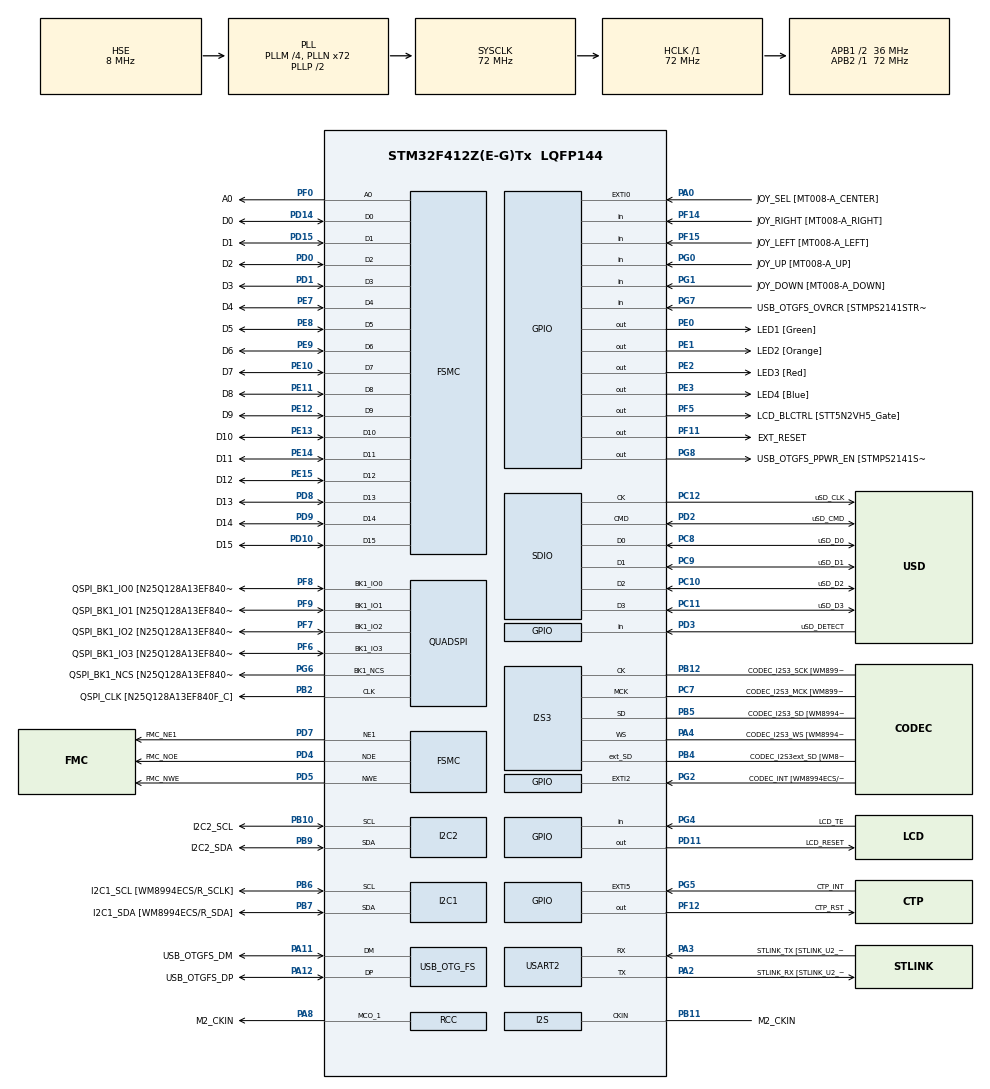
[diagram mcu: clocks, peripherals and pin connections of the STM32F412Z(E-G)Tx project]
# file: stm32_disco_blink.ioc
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PD7.Mode=NorPsramChipSelect1_1
PG8.GPIO_ModeDefaultOutputPP=GPIO_MODE_OUTPUT_OD
SH.FSMC_D1_DA1.0=FSMC_D1,16b-d1
PB10.Mode=I2C
PG8.Signal=GPIO_Output
PG4.Signal=GPIO_Input
PC12.Signal=SDIO_CK
PG6.GPIO_Label=QSPI_BK1_NCS [N25Q128A13EF840F_S]
PA14.GPIO_Label=SWCLK
SH.FSMC_NWE.0=FSMC_NWE,Lcd1
PG0.Signal=GPIO_Input
SDIO.WideMode=SDIO_BUS_WIDE_4B
PB6.GPIO_Label=I2C1_SCL [WM8994ECS/R_SCLK]
PG6.Mode=Single Bank 1
PF6.GPIO_Label=QSPI_BK1_IO3 [N25Q128A13EF840F_DQ3]
RCC.SYSCLKSource=RCC_SYSCLKSOURCE_PLLCLK
PE1.GPIO_ModeDefaultOutputPP=GPIO_MODE_OUTPUT_OD
PA4.Mode=Full_Duplex_Master
PF7.Signal=QUADSPI_BK1_IO2
PD4.Signal=FSMC_NOE
RCC.APB2TimFreq_Value=72000000
PB6.Signal=I2C1_SCL
PC7.Signal=I2S3_MCK
PB6.Mode=I2C
PD0.Signal=FSMC_D2_DA2
PD8.Signal=FSMC_D13_DA13
PE1.Signal=GPIO_Output
USB_OTG_FS.phy_itface=HCD_PHY_EMBEDDED
PB2.Signal=QUADSPI_CLK
PD1.GPIO_Label=D3
PB12.GPIO_Label=CODEC_I2S3_SCK [WM8994ECS/R_BCLK1]
PF12.GPIO_Label=CTP_RST
I2S3.ErrorAudioFreq=1.72 %
SH.FSMC_D10_DA10.0=FSMC_D10,16b-d1
PE9.Signal=FSMC_D6_DA6
SH.FSMC_A0.0=FSMC_A0,A0_1
PB1.GPIO_Label=DFSDM_DATIN0 [MP34DT01TR_DOUT]
PG4.GPIO_Label=LCD_TE
PE4.GPIO_Label=DFSDM_DATIN3 [MP23DB01MM_DOUT]
PC9.Mode=SD_4_bits_Wide_bus
PE2.Signal=GPIO_Output
PF8.Mode=Single Bank 1
PA8.Signal=RCC_MCO_1
PE10.Signal=FSMC_D7_DA7
SH.FSMC_D5_DA5.0=FSMC_D5,16b-d1
PA0.Signal=GPXTI0
Mcu.Package=LQFP144
PB9.Signal=I2C2_SDA
PB1.Signal=S_DATAIN0DFSDM1
PA10.Signal=USB_OTG_FS_ID
PE12.GPIO_Label=D9
PC11.Mode=SD_4_bits_Wide_bus
SH.FSMC_D3_DA3.0=FSMC_D3,16b-d1
PF14.Signal=GPIO_Input
RCC.APB1TimFreq_Value=72000000
PE10.GPIO_Label=D7
PA4.GPIO_Label=CODEC_I2S3_WS [WM8994ECS/R_LRCLK1]
PD15.Signal=FSMC_D1_DA1
I2S3.FullDuplexMode=I2S_FULLDUPLEXMODE_ENABLE
PD9.GPIO_Label=D14
PG5.Signal=GPXTI5
PA9.GPIO_Label=USB_OTGFS_VBUS
PD3.Signal=GPIO_Input
PH1\ -\ OSC_OUT.Mode=HSE-External-Clock-Source
PC2.Signal=S_CKOUTDFSDM1
PB11.GPIO_Label=M2_CKIN
PD7.Signal=FSMC_NE1
PD1.Signal=FSMC_D3_DA3
PA11.GPIO_Label=USB_OTGFS_DM
SH.FSMC_D9_DA9.0=FSMC_D9,16b-d1
PF14.GPIO_Label=JOY_RIGHT [MT008-A_RIGHT]
RCC.APB1CLKDivider=RCC_HCLK_DIV2
PC14-OSC32_IN.Signal=RCC_OSC32_IN
SH.FSMC_D8_DA8.0=FSMC_D8,16b-d1
PF8.GPIO_Label=QSPI_BK1_IO0 [N25Q128A13EF840F_DQ0]
USB_HOST0.BSP.STBoard=false
PD10.Signal=FSMC_D15_DA15
PA3.Mode=Asynchronous
PA8.GPIO_Label=M2_CKIN
PB11.Mode=Audio_ClockIn
PE8.GPIO_Label=D5
PA9.Signal=USB_OTG_FS_VBUS
I2S3.VirtualMode=I2S_MODE_MASTER
PE9.GPIO_Label=D6
PB10.Signal=I2C2_SCL
I2S3.AudioFreq=I2S_AUDIOFREQ_32K
PC12.Mode=SD_4_bits_Wide_bus
PH1\ -\ OSC_OUT.Signal=RCC_OSC_OUT
SH.FSMC_D7_DA7.0=FSMC_D7,16b-d1
PE1.GPIO_Label=LED2 [Orange]
USB_HOST.VirtualModeFS=Cdc
PE14.Signal=FSMC_D11_DA11
PE15.Signal=FSMC_D12_DA12
PB4.GPIO_Label=CODEC_I2S3ext_SD [WM8994ECS/R_ACDAT1]
PE8.Signal=FSMC_D5_DA5
PG7.GPIO_Label=USB_OTGFS_OVRCR [STMPS2141STR_FAULT]
SH.S_DATAIN0DFSDM1.0=DFSDM1_DATIN0
PA13.Mode=Serial_Wire
PC7.GPIO_Label=CODEC_I2S3_MCK [WM8994ECS/R_MCLK1]
PC8.Mode=SD_4_bits_Wide_bus
PA4.Signal=I2S3_WS
PB5.Signal=I2S3_SD
PE13.GPIO_Label=D10
PE3.GPIO_ModeDefaultOutputPP=GPIO_MODE_OUTPUT_OD
PD11.Signal=GPIO_Output
PC12.GPIO_Label=uSD_CLK
PA11.Signal=USB_OTG_FS_DM
SH.FSMC_D15_DA15.0=FSMC_D15,16b-d1
ProjectManager.HeapSize=0x200
PF6.Mode=Single Bank 1
PF9.Signal=QUADSPI_BK1_IO1
USB_HOST.USBH_HandleTypeDef=hUsbHostFS
NVIC.PriorityGroup=NVIC_PRIORITYGROUP_4
PF0.GPIO_Label=A0
PE3.Signal=GPIO_Output
PA8.Mode=Clock-out-1
I2S3.Instance=SPI$Index
PD2.Signal=SDIO_CMD
USB_HOST0.BSP.mode=Output
PD2.GPIO_Label=uSD_CMD
Mcu.Family=STM32F4
RCC.CortexFreq_Value=72000000
PG6.Signal=QUADSPI_BK1_NCS
PG2.Signal=GPXTI2
PE11.GPIO_Label=D8
PC10.Signal=SDIO_D2
PA0.GPIO_Label=JOY_SEL [MT008-A_CENTER]
SH.FSMC_D0_DA0.0=FSMC_D0,16b-d1
PD0.GPIO_Label=D2
PA11.Mode=Host_Only
PG5.GPIO_Label=CTP_INT
PB11.Signal=I2S_CKIN
ProjectManager.StackSize=0x400
PA12.Signal=USB_OTG_FS_DP
PH0\ -\ OSC_IN.Signal=RCC_OSC_IN
PD11.GPIO_Label=LCD_RESET
RCC.HCLKFreq_Value=72000000
PF11.GPIO_Label=EXT_RESET
PF12.Signal=GPIO_Output
USB_HOST0.BSP.ip=GPIO
RCC.AHBFreq_Value=72000000
RCC.HSE_VALUE=8000000
PE2.GPIO_ModeDefaultOutputPP=GPIO_MODE_OUTPUT_OD
PF9.Mode=Single Bank 1
PB4.Mode=Full_Duplex_Master
PE13.Signal=FSMC_D10_DA10
SH.FSMC_D14_DA14.0=FSMC_D14,16b-d1
PF7.GPIO_Label=QSPI_BK1_IO2 [N25Q128A13EF840F_DQ2]
PC14-OSC32_IN.Mode=LSE-External-Oscillator
PA14.Mode=Serial_Wire
PF11.Signal=GPIO_Output
SH.FSMC_D6_DA6.0=FSMC_D6,16b-d1
PC11.GPIO_Label=uSD_D3
PB5.Mode=Full_Duplex_Master
PA10.GPIO_Label=USB_OTGFS_ID
PB7.Signal=I2C1_SDA
USB_HOST0.BSP.i2creg=0
PE4.Signal=S_DATAIN3DFSDM1
PD7.GPIO_Label=FMC_NE1
SH.FSMC_D4_DA4.0=FSMC_D4,16b-d1
PB7.GPIO_Label=I2C1_SDA [WM8994ECS/R_SDA]
USB_HOST0.BSP.i2caddr=0
PB12.Mode=Full_Duplex_Master
USART2.VirtualMode=VM_ASYNC
PD5.GPIO_Label=FMC_NWE
NVIC.OTG_FS_IRQn=true\:0\:0\:false\:false\:true\:true\:true
PA2.GPIO_Label=STLINK_RX [STLINK_U2_RX]
SH.FSMC_D13_DA13.0=FSMC_D13,16b-d1
PF5.GPIO_Label=LCD_BLCTRL [STT5N2VH5_Gate]
USB_OTG_FS.VirtualMode=Host_Only
PF8.Signal=QUADSPI_BK1_IO0
PG0.GPIO_Label=JOY_UP [MT008-A_UP]
PE0.GPIO_Label=LED1 [Green]
PF5.Signal=GPIO_Output
USB_HOST0.BSP.name=Drive_VBUS_FS
PB5.GPIO_Label=CODEC_I2S3_SD [WM8994ECS/R_DACDAT1]
PG8.PinState=GPIO_PIN_SET
SH.FSMC_D2_DA2.0=FSMC_D2,16b-d1
PF0.Signal=FSMC_A0
PD3.GPIO_Label=uSD_DETECT
PE7.Signal=FSMC_D4_DA4
PE2.GPIO_Label=LED3 [Red]
PC2.GPIO_Label=DFSDM_CKOUT [MP34DT01TR_CLK]
PB4.Signal=I2S3_ext_SD
PG2.GPIO_Label=CODEC_INT [WM8994ECS/R_ADCLRCLK1/GPIO1]
PA3.Signal=USART2_RX
PB3.GPIO_Label=SWO
PC15-OSC32_OUT.Mode=LSE-External-Oscillator
PE0.GPIO_ModeDefaultOutputPP=GPIO_MODE_OUTPUT_OD
SH.FSMC_D12_DA12.0=FSMC_D12,16b-d1
PD15.GPIO_Label=D1
PG7.Signal=GPIO_Input
PB9.GPIO_Label=I2C2_SDA
PC10.GPIO_Label=uSD_D2
PC9.GPIO_Label=uSD_D1
PG1.Signal=GPIO_Input
PC11.Signal=SDIO_D3
PC8.Signal=SDIO_D0
USB_HOST0.BSP.solution=PG8
PC10.Mode=SD_4_bits_Wide_bus
USB_HOST.BSP.number=1
PE14.GPIO_Label=D11
PD9.Signal=FSMC_D14_DA14
PD5.Signal=FSMC_NWE
PA12.GPIO_Label=USB_OTGFS_DP
PD8.GPIO_Label=D13
PG8.GPIO_Label=USB_OTGFS_PPWR_EN [STMPS2141STR_EN]
PC8.GPIO_Label=uSD_D0
PA13.Signal=SYS_JTMS-SWDIO
PF7.Mode=Single Bank 1
PH0\ -\ OSC_IN.Mode=HSE-External-Clock-Source
PE15.GPIO_Label=D12
PF6.Signal=QUADSPI_BK1_IO3
ProjectManager.TargetToolchain=SW4STM32
PB10.GPIO_Label=I2C2_SCL
PB9.Mode=I2C
RCC.USBFreq_Value=48000000
PF9.GPIO_Label=QSPI_BK1_IO1 [N25Q128A13EF840F_DQ1]
PD10.GPIO_Label=D15
PE11.Signal=FSMC_D8_DA8
PC15-OSC32_OUT.Signal=RCC_OSC32_OUT
PD2.Mode=SD_4_bits_Wide_bus
board=STM32F412G-DISCO
RCC.VCOOutputFreq_Value=144000000
PG1.GPIO_Label=JOY_DOWN [MT008-A_DOWN]
RCC.APB2Freq_Value=72000000
USB_HOST0.BSP.api=Unknown
PD4.GPIO_Label=FMC_NOE
SH.S_CKOUTDFSDM1.0=DFSDM1_CKOUT
SH.S_DATAIN3DFSDM1.0=DFSDM1_DATIN3
PF15.GPIO_Label=JOY_LEFT [MT008-A_LEFT]
PF15.Signal=GPIO_Input
PD14.GPIO_Label=D0
Mcu.Name=STM32F412Z(E-G)Tx
PE0.Signal=GPIO_Output
PE7.GPIO_Label=D4
PE12.Signal=FSMC_D9_DA9
PA2.Signal=USART2_TX
PA13.GPIO_Label=SWDIO
PD14.Signal=FSMC_D0_DA0
RCC.48MHZClocksFreq_Value=48000000
PB3.Signal=SYS_JTDO-SWO
RCC.SYSCLKFreq_VALUE=72000000
PA12.Mode=Host_Only
VP_USB_HOST_VS_USB_HOST_CDC_FS.Mode=CDC_FS
PB2.Mode=Single Bank 1
PB7.Mode=I2C
PA14.Signal=SYS_JTCK-SWCLK
PB2.GPIO_Label=QSPI_CLK [N25Q128A13EF840F_C]
SH.FSMC_D11_DA11.0=FSMC_D11,16b-d1
SH.FSMC_NOE.0=FSMC_NOE,Lcd1
RCC.HSI_VALUE=16000000
RCC.PLLQ=3
I2S3.RealAudioFreq=32.552 KHz
RCC.PLLM=4
RCC.PLLN=72
PA2.Mode=Asynchronous
PE3.GPIO_Label=LED4 [Blue]
PH0\ -\ OSC_IN.GPIO_Label=STLK_MCO
PC9.Signal=SDIO_D1
PC7.Mode=Master_Clock_Activated
RCC.APB1Freq_Value=36000000
RCC.PLLI2SN=50
PB12.Signal=I2S3_CK
PA3.GPIO_Label=STLINK_TX [STLINK_U2_TX]
RCC.PLLI2SM=4
USB_HOST0.BSP.instance=PG8

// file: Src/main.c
/* USER CODE BEGIN Header */
/**
  ******************************************************************************
  * @file           : main.c
  * @brief          : Main program body
  ******************************************************************************
  * @attention
  *
  * <h2><center>&copy; Copyright (c) 2020 STMicroelectronics.
  * All rights reserved.</center></h2>
  *
  * This software component is licensed by ST under Ultimate Liberty license
  * SLA0044, the "License"; You may not use this file except in compliance with
  * the License. You may obtain a copy of the License at:
  *                             www.st.com/SLA0044
  *
  ******************************************************************************
  */
/* USER CODE END Header */

#include "main.h"
#include "usb_host.h"

/* USER CODE BEGIN Includes */
#include "stm32412g_discovery.h"
/* USER CODE END Includes */

I2C_HandleTypeDef hi2c1;
I2C_HandleTypeDef hi2c2;

I2S_HandleTypeDef hi2s3;

QSPI_HandleTypeDef hqspi;

SD_HandleTypeDef hsd;

UART_HandleTypeDef huart2;

SRAM_HandleTypeDef hsram1;

void SystemClock_Config(void);
static void MX_GPIO_Init(void);
static void MX_FSMC_Init(void);
static void MX_I2C1_Init(void);
static void MX_I2C2_Init(void);
static void MX_I2S3_Init(void);
static void MX_QUADSPI_Init(void);
static void MX_SDIO_SD_Init(void);
static void MX_USART2_UART_Init(void);
void MX_USB_HOST_Process(void);

int main(void)
{

  /* MCU Configuration--------------------------------------------------------*/

  /* Reset of all peripherals, Initializes the Flash interface and the Systick. */
  HAL_Init();

  /* Configure the system clock */
  SystemClock_Config();

  /* Initialize all configured peripherals */
  MX_GPIO_Init();
  MX_FSMC_Init();
  MX_I2C1_Init();
  MX_I2C2_Init();
  MX_I2S3_Init();
  MX_QUADSPI_Init();
  MX_SDIO_SD_Init();
  MX_USART2_UART_Init();
  MX_USB_HOST_Init();
  /* USER CODE BEGIN 2 */
  BSP_LED_Init(LED_BLUE);
  BSP_LED_Init(LED_RED);
  BSP_LED_Init(LED_ORANGE);
  BSP_LED_Init(LED_GREEN);

  BSP_LED_On(LED_GREEN);
  /* USER CODE END 2 */

  /* Infinite loop */
  while (1)
  {
    MX_USB_HOST_Process();

    /* USER CODE BEGIN 3 */
    BSP_LED_Toggle(LED_BLUE);

    HAL_UART_Transmit(&huart2, (uint8_t*)"BTS SNIR Sembat\r\n", 17, 1000);

    HAL_Delay(400);
  }
  /* USER CODE END 3 */
}

void SystemClock_Config(void)
{
  RCC_OscInitTypeDef RCC_OscInitStruct = {0};
  RCC_ClkInitTypeDef RCC_ClkInitStruct = {0};
  RCC_PeriphCLKInitTypeDef PeriphClkInitStruct = {0};

  /** Configure the main internal regulator output voltage
  */
  __HAL_RCC_PWR_CLK_ENABLE();
  __HAL_PWR_VOLTAGESCALING_CONFIG(PWR_REGULATOR_VOLTAGE_SCALE1);
  /** Initializes the CPU, AHB and APB busses clocks
  */
  RCC_OscInitStruct.OscillatorType = RCC_OSCILLATORTYPE_HSI|RCC_OSCILLATORTYPE_HSE;
  RCC_OscInitStruct.HSEState = RCC_HSE_BYPASS;
  RCC_OscInitStruct.HSIState = RCC_HSI_ON;
  RCC_OscInitStruct.HSICalibrationValue = RCC_HSICALIBRATION_DEFAULT;
  RCC_OscInitStruct.PLL.PLLState = RCC_PLL_ON;
  RCC_OscInitStruct.PLL.PLLSource = RCC_PLLSOURCE_HSE;
  RCC_OscInitStruct.PLL.PLLM = 4;
  RCC_OscInitStruct.PLL.PLLN = 72;
  RCC_OscInitStruct.PLL.PLLP = RCC_PLLP_DIV2;
  RCC_OscInitStruct.PLL.PLLQ = 3;
  RCC_OscInitStruct.PLL.PLLR = 2;
  if (HAL_RCC_OscConfig(&RCC_OscInitStruct) != HAL_OK)
  {
    Error_Handler();
  }
  /** Initializes the CPU, AHB and APB busses clocks
  */
  RCC_ClkInitStruct.ClockType = RCC_CLOCKTYPE_HCLK|RCC_CLOCKTYPE_SYSCLK
                              |RCC_CLOCKTYPE_PCLK1|RCC_CLOCKTYPE_PCLK2;
  RCC_ClkInitStruct.SYSCLKSource = RCC_SYSCLKSOURCE_PLLCLK;
  RCC_ClkInitStruct.AHBCLKDivider = RCC_SYSCLK_DIV1;
  RCC_ClkInitStruct.APB1CLKDivider = RCC_HCLK_DIV2;
  RCC_ClkInitStruct.APB2CLKDivider = RCC_HCLK_DIV1;

  if (HAL_RCC_ClockConfig(&RCC_ClkInitStruct, FLASH_LATENCY_2) != HAL_OK)
  {
    Error_Handler();
  }
  PeriphClkInitStruct.PeriphClockSelection = RCC_PERIPHCLK_I2S_APB1|RCC_PERIPHCLK_SDIO
                              |RCC_PERIPHCLK_CLK48;
  PeriphClkInitStruct.PLLI2S.PLLI2SN = 50;
  PeriphClkInitStruct.PLLI2S.PLLI2SM = 4;
  PeriphClkInitStruct.PLLI2S.PLLI2SR = 2;
  PeriphClkInitStruct.PLLI2S.PLLI2SQ = 2;
  PeriphClkInitStruct.Clk48ClockSelection = RCC_CLK48CLKSOURCE_PLLQ;
  PeriphClkInitStruct.SdioClockSelection = RCC_SDIOCLKSOURCE_CLK48;
  PeriphClkInitStruct.PLLI2SSelection = RCC_PLLI2SCLKSOURCE_PLLSRC;
  PeriphClkInitStruct.I2sApb1ClockSelection = RCC_I2SAPB1CLKSOURCE_PLLI2S;
  if (HAL_RCCEx_PeriphCLKConfig(&PeriphClkInitStruct) != HAL_OK)
  {
    Error_Handler();
  }
  HAL_RCC_MCOConfig(RCC_MCO1, RCC_MCO1SOURCE_HSI, RCC_MCODIV_1);
}

static void MX_I2C1_Init(void)
{

  hi2c1.Instance = I2C1;
  hi2c1.Init.ClockSpeed = 100000;
  hi2c1.Init.DutyCycle = I2C_DUTYCYCLE_2;
  hi2c1.Init.OwnAddress1 = 0;
  hi2c1.Init.AddressingMode = I2C_ADDRESSINGMODE_7BIT;
  hi2c1.Init.DualAddressMode = I2C_DUALADDRESS_DISABLE;
  hi2c1.Init.OwnAddress2 = 0;
  hi2c1.Init.GeneralCallMode = I2C_GENERALCALL_DISABLE;
  hi2c1.Init.NoStretchMode = I2C_NOSTRETCH_DISABLE;
  if (HAL_I2C_Init(&hi2c1) != HAL_OK)
  {
    Error_Handler();
  }

}

static void MX_I2C2_Init(void)
{

  hi2c2.Instance = I2C2;
  hi2c2.Init.ClockSpeed = 100000;
  hi2c2.Init.DutyCycle = I2C_DUTYCYCLE_2;
  hi2c2.Init.OwnAddress1 = 0;
  hi2c2.Init.AddressingMode = I2C_ADDRESSINGMODE_7BIT;
  hi2c2.Init.DualAddressMode = I2C_DUALADDRESS_DISABLE;
  hi2c2.Init.OwnAddress2 = 0;
  hi2c2.Init.GeneralCallMode = I2C_GENERALCALL_DISABLE;
  hi2c2.Init.NoStretchMode = I2C_NOSTRETCH_DISABLE;
  if (HAL_I2C_Init(&hi2c2) != HAL_OK)
  {
    Error_Handler();
  }

}

static void MX_I2S3_Init(void)
{

  hi2s3.Instance = SPI3;
  hi2s3.Init.Mode = I2S_MODE_MASTER_TX;
  hi2s3.Init.Standard = I2S_STANDARD_PHILIPS;
  hi2s3.Init.DataFormat = I2S_DATAFORMAT_16B;
  hi2s3.Init.MCLKOutput = I2S_MCLKOUTPUT_ENABLE;
  hi2s3.Init.AudioFreq = I2S_AUDIOFREQ_32K;
  hi2s3.Init.CPOL = I2S_CPOL_LOW;
  hi2s3.Init.ClockSource = I2S_CLOCK_PLL;
  hi2s3.Init.FullDuplexMode = I2S_FULLDUPLEXMODE_ENABLE;
  if (HAL_I2S_Init(&hi2s3) != HAL_OK)
  {
    Error_Handler();
  }

}

static void MX_QUADSPI_Init(void)
{

  /* QUADSPI parameter configuration*/
  hqspi.Instance = QUADSPI;
  hqspi.Init.ClockPrescaler = 255;
  hqspi.Init.FifoThreshold = 1;
  hqspi.Init.SampleShifting = QSPI_SAMPLE_SHIFTING_NONE;
  hqspi.Init.FlashSize = 1;
  hqspi.Init.ChipSelectHighTime = QSPI_CS_HIGH_TIME_1_CYCLE;
  hqspi.Init.ClockMode = QSPI_CLOCK_MODE_0;
  hqspi.Init.FlashID = QSPI_FLASH_ID_1;
  hqspi.Init.DualFlash = QSPI_DUALFLASH_DISABLE;
  if (HAL_QSPI_Init(&hqspi) != HAL_OK)
  {
    Error_Handler();
  }

}

static void MX_SDIO_SD_Init(void)
{

  hsd.Instance = SDIO;
  hsd.Init.ClockEdge = SDIO_CLOCK_EDGE_RISING;
  hsd.Init.ClockBypass = SDIO_CLOCK_BYPASS_DISABLE;
  hsd.Init.ClockPowerSave = SDIO_CLOCK_POWER_SAVE_DISABLE;
  hsd.Init.BusWide = SDIO_BUS_WIDE_1B;
  hsd.Init.HardwareFlowControl = SDIO_HARDWARE_FLOW_CONTROL_DISABLE;
  hsd.Init.ClockDiv = 0;
  if (HAL_SD_Init(&hsd) != HAL_OK)
  {
    Error_Handler();
  }
  if (HAL_SD_ConfigWideBusOperation(&hsd, SDIO_BUS_WIDE_4B) != HAL_OK)
  {
    Error_Handler();
  }

}

static void MX_USART2_UART_Init(void)
{

  huart2.Instance = USART2;
  huart2.Init.BaudRate = 115200;
  huart2.Init.WordLength = UART_WORDLENGTH_8B;
  huart2.Init.StopBits = UART_STOPBITS_1;
  huart2.Init.Parity = UART_PARITY_NONE;
  huart2.Init.Mode = UART_MODE_TX_RX;
  huart2.Init.HwFlowCtl = UART_HWCONTROL_NONE;
  huart2.Init.OverSampling = UART_OVERSAMPLING_16;
  if (HAL_UART_Init(&huart2) != HAL_OK)
  {
    Error_Handler();
  }

}

static void MX_GPIO_Init(void)
{
  GPIO_InitTypeDef GPIO_InitStruct = {0};

  /* GPIO Ports Clock Enable */
  __HAL_RCC_GPIOE_CLK_ENABLE();
  __HAL_RCC_GPIOC_CLK_ENABLE();
  __HAL_RCC_GPIOF_CLK_ENABLE();
  __HAL_RCC_GPIOH_CLK_ENABLE();
  __HAL_RCC_GPIOA_CLK_ENABLE();
  __HAL_RCC_GPIOB_CLK_ENABLE();
  __HAL_RCC_GPIOG_CLK_ENABLE();
  __HAL_RCC_GPIOD_CLK_ENABLE();

  /*Configure GPIO pin Output Level */
  HAL_GPIO_WritePin(GPIOE, LED3_Pin|LED4_Pin|LED1_Pin|LED2_Pin, GPIO_PIN_RESET);

  /*Configure GPIO pin Output Level */
  HAL_GPIO_WritePin(GPIOF, LCD_BLCTRL_Pin|EXT_RESET_Pin|CTP_RST_Pin, GPIO_PIN_RESET);

  /*Configure GPIO pin Output Level */
  HAL_GPIO_WritePin(LCD_RESET_GPIO_Port, LCD_RESET_Pin, GPIO_PIN_RESET);

  /*Configure GPIO pin Output Level */
  HAL_GPIO_WritePin(USB_OTGFS_PPWR_EN_GPIO_Port, USB_OTGFS_PPWR_EN_Pin, GPIO_PIN_SET);

  /*Configure GPIO pins : LED3_Pin LED4_Pin LED1_Pin LED2_Pin */
  GPIO_InitStruct.Pin = LED3_Pin|LED4_Pin|LED1_Pin|LED2_Pin;
  GPIO_InitStruct.Mode = GPIO_MODE_OUTPUT_OD;
  GPIO_InitStruct.Pull = GPIO_NOPULL;
  GPIO_InitStruct.Speed = GPIO_SPEED_FREQ_LOW;
  HAL_GPIO_Init(GPIOE, &GPIO_InitStruct);

  /*Configure GPIO pin : DFSDM_DATIN3_Pin */
  GPIO_InitStruct.Pin = DFSDM_DATIN3_Pin;
  GPIO_InitStruct.Mode = GPIO_MODE_AF_PP;
  GPIO_InitStruct.Pull = GPIO_NOPULL;
  GPIO_InitStruct.Speed = GPIO_SPEED_FREQ_LOW;
  GPIO_InitStruct.Alternate = GPIO_AF8_DFSDM1;
  HAL_GPIO_Init(DFSDM_DATIN3_GPIO_Port, &GPIO_InitStruct);

  /*Configure GPIO pins : LCD_BLCTRL_Pin EXT_RESET_Pin CTP_RST_Pin */
  GPIO_InitStruct.Pin = LCD_BLCTRL_Pin|EXT_RESET_Pin|CTP_RST_Pin;
  GPIO_InitStruct.Mode = GPIO_MODE_OUTPUT_PP;
  GPIO_InitStruct.Pull = GPIO_NOPULL;
  GPIO_InitStruct.Speed = GPIO_SPEED_FREQ_LOW;
  HAL_GPIO_Init(GPIOF, &GPIO_InitStruct);

  /*Configure GPIO pin : DFSDM_CKOUT_Pin */
  GPIO_InitStruct.Pin = DFSDM_CKOUT_Pin;
  GPIO_InitStruct.Mode = GPIO_MODE_AF_PP;
  GPIO_InitStruct.Pull = GPIO_NOPULL;
  GPIO_InitStruct.Speed = GPIO_SPEED_FREQ_LOW;
  GPIO_InitStruct.Alternate = GPIO_AF8_DFSDM1;
  HAL_GPIO_Init(DFSDM_CKOUT_GPIO_Port, &GPIO_InitStruct);

  /*Configure GPIO pin : JOY_SEL_Pin */
  GPIO_InitStruct.Pin = JOY_SEL_Pin;
  GPIO_InitStruct.Mode = GPIO_MODE_IT_RISING;
  GPIO_InitStruct.Pull = GPIO_NOPULL;
  HAL_GPIO_Init(JOY_SEL_GPIO_Port, &GPIO_InitStruct);

  /*Configure GPIO pin : DFSDM_DATIN0_Pin */
  GPIO_InitStruct.Pin = DFSDM_DATIN0_Pin;
  GPIO_InitStruct.Mode = GPIO_MODE_AF_PP;
  GPIO_InitStruct.Pull = GPIO_NOPULL;
  GPIO_InitStruct.Speed = GPIO_SPEED_FREQ_LOW;
  GPIO_InitStruct.Alternate = GPIO_AF8_DFSDM1;
  HAL_GPIO_Init(DFSDM_DATIN0_GPIO_Port, &GPIO_InitStruct);

  /*Configure GPIO pins : JOY_RIGHT_Pin JOY_LEFT_Pin */
  GPIO_InitStruct.Pin = JOY_RIGHT_Pin|JOY_LEFT_Pin;
  GPIO_InitStruct.Mode = GPIO_MODE_INPUT;
  GPIO_InitStruct.Pull = GPIO_NOPULL;
  HAL_GPIO_Init(GPIOF, &GPIO_InitStruct);

  /*Configure GPIO pins : JOY_UP_Pin JOY_DOWN_Pin LCD_TE_Pin USB_OTGFS_OVRCR_Pin */
  GPIO_InitStruct.Pin = JOY_UP_Pin|JOY_DOWN_Pin|LCD_TE_Pin|USB_OTGFS_OVRCR_Pin;
  GPIO_InitStruct.Mode = GPIO_MODE_INPUT;
  GPIO_InitStruct.Pull = GPIO_NOPULL;
  HAL_GPIO_Init(GPIOG, &GPIO_InitStruct);

  /*Configure GPIO pin : M2_CKIN_Pin */
  GPIO_InitStruct.Pin = M2_CKIN_Pin;
  GPIO_InitStruct.Mode = GPIO_MODE_AF_PP;
  GPIO_InitStruct.Pull = GPIO_NOPULL;
  GPIO_InitStruct.Speed = GPIO_SPEED_FREQ_LOW;
  GPIO_InitStruct.Alternate = GPIO_AF5_SPI1;
  HAL_GPIO_Init(M2_CKIN_GPIO_Port, &GPIO_InitStruct);

  /*Configure GPIO pin : LCD_RESET_Pin */
  GPIO_InitStruct.Pin = LCD_RESET_Pin;
  GPIO_InitStruct.Mode = GPIO_MODE_OUTPUT_PP;
  GPIO_InitStruct.Pull = GPIO_NOPULL;
  GPIO_InitStruct.Speed = GPIO_SPEED_FREQ_LOW;
  HAL_GPIO_Init(LCD_RESET_GPIO_Port, &GPIO_InitStruct);

  /*Configure GPIO pins : CODEC_INT_Pin CTP_INT_Pin */
  GPIO_InitStruct.Pin = CODEC_INT_Pin|CTP_INT_Pin;
  GPIO_InitStruct.Mode = GPIO_MODE_IT_RISING;
  GPIO_InitStruct.Pull = GPIO_NOPULL;
  HAL_GPIO_Init(GPIOG, &GPIO_InitStruct);

  /*Configure GPIO pin : USB_OTGFS_PPWR_EN_Pin */
  GPIO_InitStruct.Pin = USB_OTGFS_PPWR_EN_Pin;
  GPIO_InitStruct.Mode = GPIO_MODE_OUTPUT_OD;
  GPIO_InitStruct.Pull = GPIO_NOPULL;
  GPIO_InitStruct.Speed = GPIO_SPEED_FREQ_LOW;
  HAL_GPIO_Init(USB_OTGFS_PPWR_EN_GPIO_Port, &GPIO_InitStruct);

  /*Configure GPIO pin : M2_CKINA8_Pin */
  GPIO_InitStruct.Pin = M2_CKINA8_Pin;
  GPIO_InitStruct.Mode = GPIO_MODE_AF_PP;
  GPIO_InitStruct.Pull = GPIO_NOPULL;
  GPIO_InitStruct.Speed = GPIO_SPEED_FREQ_LOW;
  GPIO_InitStruct.Alternate = GPIO_AF0_MCO;
  HAL_GPIO_Init(M2_CKINA8_GPIO_Port, &GPIO_InitStruct);

  /*Configure GPIO pin : uSD_DETECT_Pin */
  GPIO_InitStruct.Pin = uSD_DETECT_Pin;
  GPIO_InitStruct.Mode = GPIO_MODE_INPUT;
  GPIO_InitStruct.Pull = GPIO_NOPULL;
  HAL_GPIO_Init(uSD_DETECT_GPIO_Port, &GPIO_InitStruct);

}

/* FSMC initialization function */
static void MX_FSMC_Init(void)
{

  FSMC_NORSRAM_TimingTypeDef Timing = {0};

  /** Perform the SRAM1 memory initialization sequence
  */
  hsram1.Instance = FSMC_NORSRAM_DEVICE;
  hsram1.Extended = FSMC_NORSRAM_EXTENDED_DEVICE;
  /* hsram1.Init */
  hsram1.Init.NSBank = FSMC_NORSRAM_BANK1;
  hsram1.Init.DataAddressMux = FSMC_DATA_ADDRESS_MUX_DISABLE;
  hsram1.Init.MemoryType = FSMC_MEMORY_TYPE_SRAM;
  hsram1.Init.MemoryDataWidth = FSMC_NORSRAM_MEM_BUS_WIDTH_16;
  hsram1.Init.BurstAccessMode = FSMC_BURST_ACCESS_MODE_DISABLE;
  hsram1.Init.WaitSignalPolarity = FSMC_WAIT_SIGNAL_POLARITY_LOW;
  hsram1.Init.WaitSignalActive = FSMC_WAIT_TIMING_BEFORE_WS;
  hsram1.Init.WriteOperation = FSMC_WRITE_OPERATION_ENABLE;
  hsram1.Init.WaitSignal = FSMC_WAIT_SIGNAL_DISABLE;
  hsram1.Init.ExtendedMode = FSMC_EXTENDED_MODE_DISABLE;
  hsram1.Init.AsynchronousWait = FSMC_ASYNCHRONOUS_WAIT_DISABLE;
  hsram1.Init.WriteBurst = FSMC_WRITE_BURST_DISABLE;
  hsram1.Init.ContinuousClock = FSMC_CONTINUOUS_CLOCK_SYNC_ONLY;
  hsram1.Init.WriteFifo = FSMC_WRITE_FIFO_ENABLE;
  hsram1.Init.PageSize = FSMC_PAGE_SIZE_NONE;
  /* Timing */
  Timing.AddressSetupTime = 15;
  Timing.AddressHoldTime = 15;
  Timing.DataSetupTime = 255;
  Timing.BusTurnAroundDuration = 15;
  Timing.CLKDivision = 16;
  Timing.DataLatency = 17;
  Timing.AccessMode = FSMC_ACCESS_MODE_A;
  /* ExtTiming */

  if (HAL_SRAM_Init(&hsram1, &Timing, NULL) != HAL_OK)
  {
    Error_Handler( );
  }

}

void Error_Handler(void)
{
}

/************************ (C) COPYRIGHT STMicroelectronics *****END OF FILE****/
